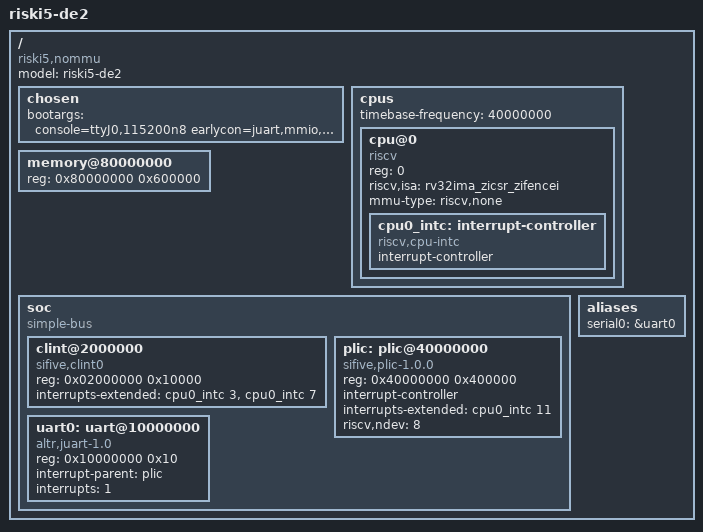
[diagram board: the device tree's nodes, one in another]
/*
 * SPDX-FileCopyrightText: 2026 Mika Tammi
 * SPDX-License-Identifier: MIT OR BSD-3-Clause
 *
 * Device tree for the riski5 SoC on the Altera DE2 (Cyclone II
 * EP2C35F672C6) board.
 *
 * Reflects the SoC layout after the L-0 CLINT refactor:
 *
 *   - One RV32IMA + Zicsr + Zifencei hart, no MMU (nommu Linux).
 *   - 8 MB SDRAM @ 0x8000_0000 (only RAM region).
 *   - SiFive CLINT @ 0x0200_0000 (mtime / mtimecmp / msip).
 *   - SiFive PLIC @ 0x4000_0000 (8 sources, 1 hart context).
 *   - Altera JTAG-UART @ 0x1000_0000 (16 B MMIO window),
 *     IRQ 1 on the PLIC (set in Riski5.Soc.plicExtIrqsS).
 *   - 40 MHz core clock.
 *
 * Compatible-strings + reg sizes match the upstream Linux drivers
 * we're targeting:
 *
 *   - drivers/clocksource/timer-clint.c — "sifive,clint0"
 *   - drivers/irqchip/irq-sifive-plic.c — "sifive,plic-1.0.0"
 *   - drivers/tty/serial/altera_jtaguart.c — "altr,juart-1.0"
 *
 * The L-3b SDRAM-loader places the kernel image at the bottom of
 * SDRAM (0x8000_0000) and the cpio initramfs at +4 MB
 * (0x8040_0000). The kernel's expected layout for nommu boot is:
 *
 *   [0x8000_0000 .. 0x8040_0000)   kernel image (4 MB max)
 *   [0x8040_0000 .. 0x8080_0000)   initramfs cpio (4 MB max)
 *
 * If either grows past 4 MB the boundaries need to move; track
 * that in docs/linux-boot.md.
 */

/dts-v1/;
/ {
	#address-cells = <1>;
	#size-cells = <1>;
	compatible = "riski5,nommu";
	model = "riski5-de2";

	chosen {
		/*
		 * earlycon: the Linux altera_jtaguart driver registers
		 * its earlycon under the name "juart" (not "jtag-uart"
		 * as one might guess from the device's compatible
		 * string). The OF_EARLYCON_DECLARE that drives this
		 * lives in drivers/tty/serial/altera_jtaguart.c:
		 *
		 *   OF_EARLYCON_DECLARE(juart, "altr,juart-1.0",
		 *                       altera_jtaguart_earlycon_setup);
		 *
		 * Wrong name → silent earlycon, kernel boot indistinguishable
		 * from a hung head.S until the regular console comes up.
		 *
		 * verbose loglevel=8 (KERN_DEBUG) and ignore_loglevel get
		 * everything onto the wire from the first printk; debug
		 * keeps the floor of CONFIG_DYNAMIC_DEBUG enabled in case
		 * any subsystem we care about uses pr_debug().
		 */
		bootargs = "console=ttyJ0,115200n8 earlycon=juart,mmio,0x10000000 keep_bootcon loglevel=8 ignore_loglevel debug rdinit=/init initcall_debug initcall_blacklist=deferred_probe_initcall,init_pipe_fs";
		/*
		 * initrd window — DISABLED for #64 hwsim run. The DTB
		 * is loaded at 0x80400000 itself, so pointing initrd
		 * there means kernel tries to unpack the DTB as cpio
		 * (fails), then wedges in flush_delayed_fput. Embedded
		 * initramfs (CONFIG_INITRAMFS_SOURCE) provides /init.
		 * Re-enable when hwsim loads a real cpio at a separate
		 * address (e.g. 0x80700000) and update both ends.
		 */
		// linux,initrd-start = <0x80700000>;
		// linux,initrd-end   = <0x80800000>;
	};

	cpus {
		#address-cells = <1>;
		#size-cells = <0>;
		/* Core clock: 40 MHz. mtime increments at the same
		 * rate (CLINT runs on the core clock; phase 2D PLLs
		 * may decouple them). */
		timebase-frequency = <40000000>;

		cpu@0 {
			device_type = "cpu";
			reg = <0>;
			compatible = "riscv";
			riscv,isa = "rv32ima_zicsr_zifencei";
			mmu-type = "riscv,none";
			status = "okay";

			cpu0_intc: interrupt-controller {
				#address-cells = <0>;
				#interrupt-cells = <1>;
				interrupt-controller;
				compatible = "riscv,cpu-intc";
			};
		};
	};

	memory@80000000 {
		device_type = "memory";
		/* 6 MB instead of 8 MB. Workaround for #64 follow-up:
		 * /init binary was being allocated to 0x807cc000 by the
		 * BFLT loader and reading back as 0xffff (uninitialized
		 * SDRAM pattern), suggesting the data-port write path may
		 * not consistently land at 0x807c0000+. By restricting the
		 * kernel's memory to 6 MB, the page allocator stays inside
		 * 0x80000000..0x80600000 where every test we have proves
		 * SDRAM is reliable. Drop back to 8 MB once the high-half
		 * write path is independently verified.  */
		reg = <0x80000000 0x600000>;  /* 6 MB */
	};

	soc {
		#address-cells = <1>;
		#size-cells = <1>;
		compatible = "simple-bus";
		ranges;

		clint@2000000 {
			compatible = "sifive,clint0", "riscv,clint0";
			reg = <0x02000000 0x10000>;
			interrupts-extended = <&cpu0_intc 3 &cpu0_intc 7>;
		};

		plic: plic@40000000 {
			compatible = "sifive,plic-1.0.0";
			reg = <0x40000000 0x400000>;  /* 4 MB */
			interrupt-controller;
			#interrupt-cells = <1>;
			#address-cells = <0>;
			interrupts-extended = <&cpu0_intc 11>;
			riscv,ndev = <8>;  /* 8 sources max */
		};

		uart0: uart@10000000 {
			compatible = "altr,juart-1.0";
			reg = <0x10000000 0x10>;
			interrupt-parent = <&plic>;
			interrupts = <1>;
		};
	};

	aliases {
		serial0 = &uart0;
	};
};
